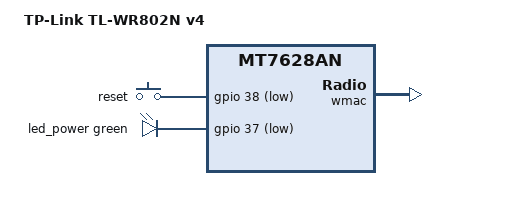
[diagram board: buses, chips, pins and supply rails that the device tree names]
// SPDX-License-Identifier: GPL-2.0-or-later OR MIT

#include <dt-bindings/leds/common.h>

#include "mt7628an_tplink_8m.dtsi"

/ {
	compatible = "tplink,tl-wr802n-v4", "mediatek,mt7628an-soc";
	model = "TP-Link TL-WR802N v4";

	aliases {
		led-boot = &led_power;
		led-failsafe = &led_power;
		led-running = &led_power;
		led-upgrade = &led_power;
	};

	keys {
		compatible = "gpio-keys";

		reset {
			label = "reset";
			gpios = <&gpio 38 GPIO_ACTIVE_LOW>;
			linux,code = <KEY_RESTART>;
		};
	};

	leds {
		compatible = "gpio-leds";

		led_power: power {
			function = LED_FUNCTION_POWER;
			color = <LED_COLOR_ID_GREEN>;
			gpios = <&gpio 37 GPIO_ACTIVE_LOW>;
		};
	};
};

&ehci {
	status = "disabled";
};

&ohci {
	status = "disabled";
};

&state_default {
	gpio {
		groups = "refclk", "wdt";
		function = "gpio";
	};
};

&ethernet {
	nvmem-cells = <&macaddr_factory_f100 0>;
	nvmem-cell-names = "mac-address";
};

&wmac {
	status = "okay";

	nvmem-cells = <&eeprom_factory_20000>, <&macaddr_factory_f100 0>;
	nvmem-cell-names = "eeprom", "mac-address";
};
